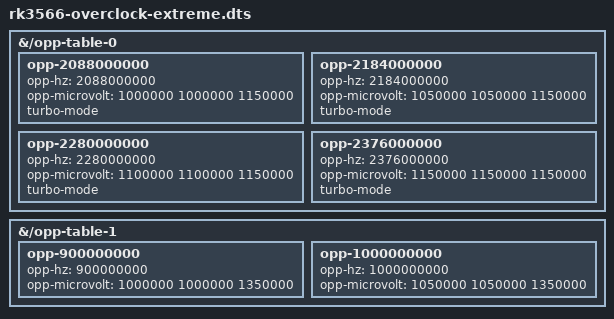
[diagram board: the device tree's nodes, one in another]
/*
 * RK3566 Extreme Overclock
 *
 * CPU: Turbo boost OPPs with undervolted curve.
 *   2088 MHz @ 1000mV (50mV below stock — validated stable)
 *   2184 MHz @ 1050mV (50mV below stock — validated stable)
 *   2280 MHz @ 1100mV (same voltage as stock 2184, +4.4% freq)
 *   2376 MHz @ 1150mV (regulator ceiling)
 *
 * GPU: Add 900/1000 MHz OPPs.
 *
 * WARNING: Not all silicon is stable at 2376 MHz. Test with
 * sustained load (stress-ng --cpu 4) before relying on this.
 * Stack with an undervolt DTBO for best thermals.
 */
/dts-v1/;
/plugin/;

/ {
fragment@0 {
	target-path = "/opp-table-0";
	__overlay__ {
		opp-2088000000 {
			opp-hz = /bits/ 64 <2088000000>;
			opp-microvolt = <1000000 1000000 1150000>;
			turbo-mode;
		};
		opp-2184000000 {
			opp-hz = /bits/ 64 <2184000000>;
			opp-microvolt = <1050000 1050000 1150000>;
			turbo-mode;
		};
		opp-2280000000 {
			opp-hz = /bits/ 64 <2280000000>;
			opp-microvolt = <1100000 1100000 1150000>;
			turbo-mode;
		};
		opp-2376000000 {
			opp-hz = /bits/ 64 <2376000000>;
			opp-microvolt = <1150000 1150000 1150000>;
			turbo-mode;
		};
	};
};
fragment@1 {
	target-path = "/opp-table-1";
	__overlay__ {
		opp-900000000 {
			opp-hz = /bits/ 64 <900000000>;
			opp-microvolt = <1000000 1000000 1350000>;
		};
		opp-1000000000 {
			opp-hz = /bits/ 64 <1000000000>;
			opp-microvolt = <1050000 1050000 1350000>;
		};
	};
};
};
